# nrf7140_wificore register map
Vendor: Nordic Semiconductor; Series: nRF71; File version: 1
Registers are 32-bit, read-write, reset 0x0 unless marked. A register's access mark holds for its fields unless they carry their own. Offsets are from the block's base; [hi:lo] are bit positions; lines under a group give offsets from that group; {n}, {i} and the like mark numbered series.

## RPUQM
Base 0x480BE000
0x00 UCC_QM_PERIP group — Unspecified
  0x00 CONTROL0 — UCC QM PERIP CONTROL 0
    [23] RSQUEUE — Writing a 1 to this bit causes all queues to be reset to their default stateThis bit is cleared automatically after it has taken effect.
  0x04 ERRORCLEAR — UCC QM PERIP ERROR CLEAR
    [23] ERRFLAGCLR — Writing 1 to this bit clears the UNDERFLOW and OVERFLOW bits in this register.The QM_ERROR event flag will be clear following this action for either state of ERR_FLAG_EN.This bit is cleared automatically after it has taken effect.
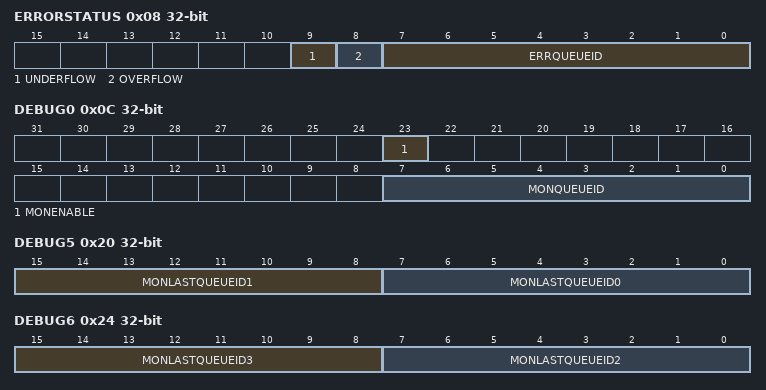
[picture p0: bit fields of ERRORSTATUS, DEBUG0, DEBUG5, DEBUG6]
  0x08 ERRORSTATUS ro — UCC QM PERIP ERROR STATUS
    [9] UNDERFLOW — The least recent queue error was an underflow.This field is read-only
    [8] OVERFLOW — The least recent queue error was an overflow.This field is read-only
    [7:0] ERRQUEUEID — The ID number of the queue which caused the least recent error.This field is read-only
  0x0C DEBUG0 — UCC QM PERIP DEBUG 0
    [23] MONENABLE
      0=Debug Monitor disabled (default power saving mode); 1=DebugMonitorEnabled
    [7:0] MONQUEUEID — The ID number of the queue to be monitored.Writing any value to this field sets MAX_COUNT to zero.
  0x10 DEBUG1 ro — UCC QM PERIP DEBUG 1
    [12:0] MONMAXCOUNT — The maximum value of count seen for queue MON_QUEUE_ID since the last write to the QM_PERIP_DEBUG_0 register
  0x14 DEBUG2 ro — UCC QM PERIP DEBUG 2
    [12:0] MONCOUNT — The value of count for the monitored queue MON_QUEUE_ID
  0x18 DEBUG3 ro — UCC QM PERIP DEBUG 3
    [23] MONNOTEMPTY — The NOT_EMPTY flag for the monitored queue MON_QUEUE_ID
  0x1C DEBUG4 ro reset 0x800000 — UCC QM PERIP DEBUG 4
    [23] MONNOTFULL — The NOT_FULL flag for the monitored queue MON_QUEUE_ID
  0x20 DEBUG5 ro — UCC QM PERIP DEBUG 5
    [15:8] MONLASTQUEUEID1 — The id of the second queue from the latest written
    [7:0] MONLASTQUEUEID0 — The id of the last queue written
  0x24 DEBUG6 ro — UCC QM PERIP DEBUG 6
    [15:8] MONLASTQUEUEID3 — The id of the fourth queue from the latest written
    [7:0] MONLASTQUEUEID2 — The id of the third queue from the latest written
  0x28 BUILD0 ro — UCC QM PERIP BUILD 0
    [7:0] BUILDMAXNUMQUEUES — The highest queue ID supported by this instance of the Queue Manager. (15 to 255)
  {0x2C+4j} COUNTONLY[{j}] (j=0..15) — Description collection: UCC QM PERIP COUNT ONLY
    [15:0] COUNTONLY — The COUNT_ONLY flag for queues N*16 + 15 to N*16
  {0x400+4j} HEAD[{j}] (j=0..255) — Description collection: UCC QM PERIP HEAD
    [23:0] HEADDATA — Reading this register returns the data item at the head of queue [n].Writing any value to this register causes one item to be popped from the head of queue [n].
  {0x800+4j} TAIL[{j}] (j=0..255) — Description collection: UCC QM PERIP TAIL
    [23:0] TAILDATA — Reading this register returns the value zero.Data written to this register is added to the tail of queue [n].

## GLOBAL_MUTEX120 — MUTEX 0
Base 0x4F8D2000
Same registers: GLOBAL_MUTEX130 0x4F927000
{0x400+4i} MUTEX[{i}] (i=0..31) — Description collection: Mutex register
  [0] MUTEX — Mutex register n
    0=Unlocked (Mutex n is in unlocked state); 1=Locked (Mutex n is in locked state)

## GLOBAL_PROTOTYPE — Prototype HW information registers.
Base 0x4F8D2000; alternate view of GLOBAL_MUTEX120
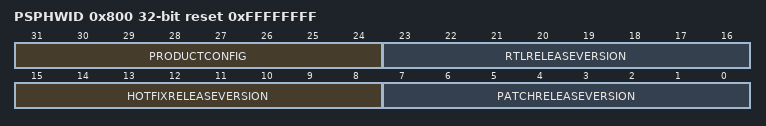
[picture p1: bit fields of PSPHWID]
0x800 PSPHWID ro reset 0xFFFFFFFF — PSP hardware ID register, unique ID for each prototype release. Used to identify RTL release that prototype is based on.
  [31:24] PRODUCTCONFIG
  [23:16] RTLRELEASEVERSION — First letter of RTL release version in ASCII corresponding to A-Z.
  [15:8] HOTFIXRELEASEVERSION
  [7:0] PATCHRELEASEVERSION — PSP patch/bugfix release version
0x804 FPGATIMESTAMP ro — 32-bit timestamp value stored by the FPGA bitstream in format ddddd_MMMM_yyyyyy_hhhhh_mmmmmm_ssssss. Unique for every FPGA netlist implementation, not dependent to RTL synthesis. 0x87654321 set in emulator database.
  [31:0] FPGATIMESTAMP — ddddd = 5 bits to represent 31 days in a month. MMMM = 4 bits to represent 12 months in a year. yyyyyy = 6 bits to represent 0 to 63 (to note year 2000 to 2063). hhhhh = 5 bits to represent 24 hours in a day. mmmmmm = 6 bits to represent 60 minutes in an hour. ssssss = 6 bits to represent 60 seconds in a minute.
0x808 EMULATORSPEEDVALUE ro — Used to store real speed of emulator is running. Used by SW to config UART speed etc, to ensure correct operation.
  [31:0] EMULATORSPEEDVALUE — Actual clock speed for FCLK 400M in emulator (Hz). In FPGA set to 0x0.
0x80C FPGACLOCKDIVIDERRATIO ro — Overall clock divider ratio for FPGA
  [31:0] FPGACLOCKDIVIDERRATIO — Overall clock divider ratio for FPGA. Set to 0 for emulator database.
